# him register map
Vendor: Texas Instruments
Peripheral module from a debugger description file (folder sc4e129bnczad).
Registers are 32-bit, read-write, no defined reset value unless marked. A register's access mark holds for its fields unless they carry their own. Offsets are as the file gives them; lines under a group give offsets from that group; [hi:lo] are bit positions; {n}, {i} and the like mark numbered series; 'fields as' and 'values as' point back to an identical list; <NAME> marks a mode.

## HIM0 — Human Interface Module register offsets
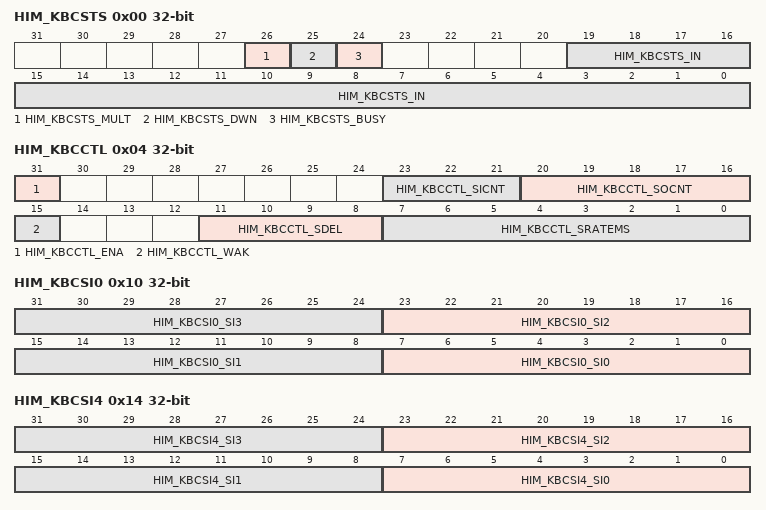
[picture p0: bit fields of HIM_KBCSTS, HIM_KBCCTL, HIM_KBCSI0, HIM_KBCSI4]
0x00 HIM_KBCSTS ro — HIM KBC Status
  [26] HIM_KBCSTS_MULT — Multi-key Detect
  [25] HIM_KBCSTS_DWN — Key Down
  [24] HIM_KBCSTS_BUSY — Scan Busy
  [19:0] HIM_KBCSTS_IN — Scan-Input Byte Change
0x04 HIM_KBCCTL — HIM KBC Control
  [31] HIM_KBCCTL_ENA — Key Scan Enable
  [23:21] HIM_KBCCTL_SICNT — Scan-In Pins
  [20:16] HIM_KBCCTL_SOCNT — Scan-Out Pins
  [15] HIM_KBCCTL_WAK — Wake Test Enable
  [11:8] HIM_KBCCTL_SDEL — Scan-in Delay
  [7:0] HIM_KBCCTL_SRATEMS — Sample Rate (in ms)
0x10 HIM_KBCSI0 ro — HIM KBC Scan-In 0
  [8n+7:8n] HIM_KBCSI0_SI{n} (n=0..3) — SI{n} Read Key States
0x14 HIM_KBCSI4 ro — HIM KBC Scan-In 4
  [8n+7:8n] HIM_KBCSI4_SI{n} (n=0..3) — SI{n} Read Key States
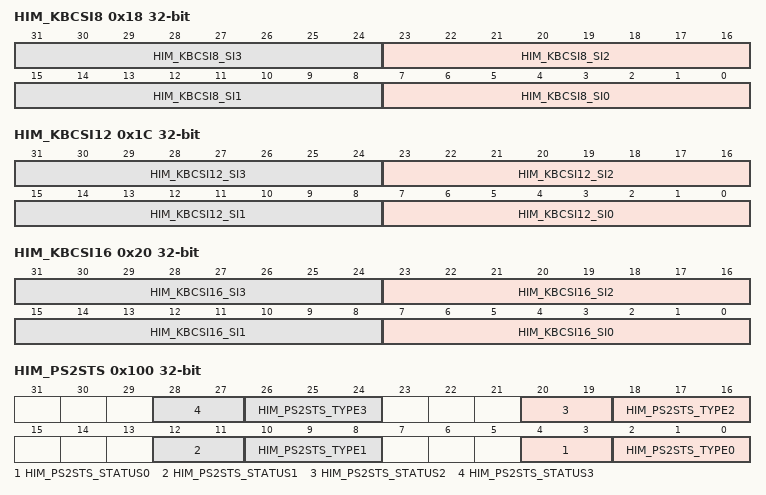
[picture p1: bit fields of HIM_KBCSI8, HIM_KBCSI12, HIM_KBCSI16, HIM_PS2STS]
0x18 HIM_KBCSI8 ro — HIM KBC Scan-In 8
  [8n+7:8n] HIM_KBCSI8_SI{n} (n=0..3) — SI{n} Read Key States
0x1C HIM_KBCSI12 ro — HIM KBC Scan-In 12
  [8n+7:8n] HIM_KBCSI12_SI{n} (n=0..3) — SI{n} Read Key States
0x20 HIM_KBCSI16 ro — HIM KBC Scan-In 16
  [8n+7:8n] HIM_KBCSI16_SI{n} (n=0..3) — SI{n} Read Key States
0x100 HIM_PS2STS ro — HIM PS/2 Status
  [8n+4:8n+3] HIM_PS2STS_STATUS{n} (n=0..3) — PS/2 Bus {n} Line Status
    0=HIM_PS2STS_STATUS{n}_IDLE (Idle); 1=HIM_PS2STS_STATUS{n}_INHIBIT (Inhibited); 2=HIM_PS2STS_STATUS{n}_BUSY (Busy); 3=HIM_PS2STS_STATUS{n}_TRANSIT (Bus is transitioning)
  [8n+2:8n] HIM_PS2STS_TYPE{n} (n=0..3) — Data Type Received
    0=HIM_PS2STS_TYPE{n}_NODATA (No Data Received); 1=HIM_PS2STS_TYPE{n}_ACK (ACK); 2=HIM_PS2STS_TYPE{n}_ERESPS (Error in response to command); 3=HIM_PS2STS_TYPE{n}_CMD (Response to command); 6=HIM_PS2STS_TYPE{n}_ERR (Captured error); 7=HIM_PS2STS_TYPE{n}_DATA (Captured received data)
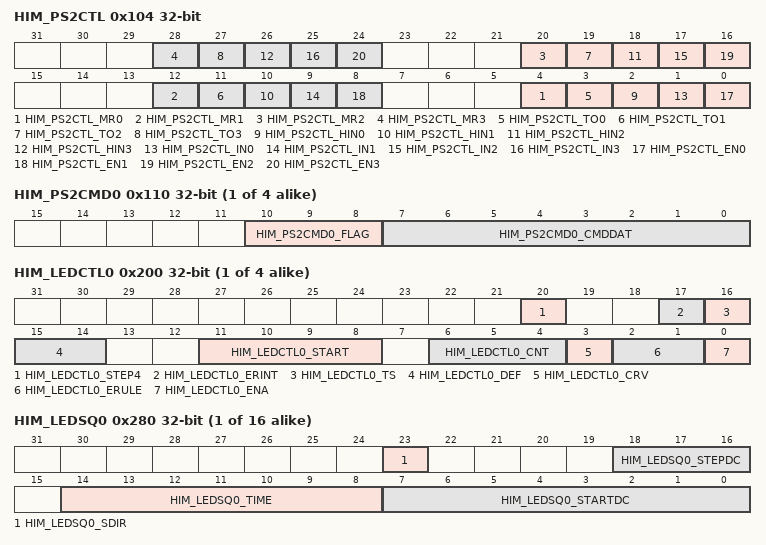
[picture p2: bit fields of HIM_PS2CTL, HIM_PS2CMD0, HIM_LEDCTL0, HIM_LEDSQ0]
0x104 HIM_PS2CTL — HIM PS/2 Control
  [8n+4] HIM_PS2CTL_MR{n} (n=0..3) — More Read Data Indication PS/2 Bus {n}
  [8n+3] HIM_PS2CTL_TO{n} (n=0..3) — Time Out Detection Enable PS/2 Bus {n}
  [8n+2] HIM_PS2CTL_HIN{n} (n=0..3) — Hold Inhibit State Enable PS/2 Bus {n}
  [8n+1] HIM_PS2CTL_IN{n} (n=0..3) — Inhibit Enable PS/2 Bus {n}
  [8n] HIM_PS2CTL_EN{n} (n=0..3) — PS/2 Bus {n} Enable
{0x110+8i} HIM_PS2CMD{i} (i=0..3) — HIM PS/2 {i} Command
  [10:8] HIM_PS2CMD{i}_FLAG — PS/2 Command Flags
    0=HIM_PS2CMD{i}_FLAG_NONE (No ACK Expected); 1=HIM_PS2CMD{i}_FLAG_NOACK (Response Data expected back with no ACK); 2=HIM_PS2CMD{i}_FLAG_NOACK_2 (No ACK with two bytes of Response Data expected back); 3=HIM_PS2CMD{i}_FLAG_NOACK_3 (No ACK with three bytes of Response Data expected back); 4=HIM_PS2CMD{i}_FLAG_ACK (ACK (0xFA) expected proceeded by 0 to 3 bytes of data); 5=HIM_PS2CMD{i}_FLAG_ACK_1 (ACK with one byte of Response Data expected back); 6=HIM_PS2CMD{i}_FLAG_ACK_2 (ACK with two bytes of Response Data expected back); 7=HIM_PS2CMD{i}_FLAG_ACK_3 (ACK with three bytes of Response Data expected back)
  [7:0] HIM_PS2CMD{i}_CMDDAT — Command Data
{0x114+8i} HIM_PS2RDAT{i} (i=0..3) — HIM PS/2 {i} Receive Data
  [7:0] HIM_PS2RDAT{i}_DATA — Last Data Byte
{0x200+4i} HIM_LEDCTL{i} (i=0..3) — LED {i} Control
  [20] HIM_LEDCTL{i}_STEP4 — Step Rule
  [17] HIM_LEDCTL{i}_ERINT — Reverse Mode End Rule (ERULE) Interrupt Control
  [16] HIM_LEDCTL{i}_TS — Tri-stated Off
  [15:14] HIM_LEDCTL{i}_DEF — Default Duty Cycle State
    0=HIM_LEDCTL{i}_DEF_LAST (The LED duty cycle is the (final) value that exists at end of rule with stop); 1=HIM_LEDCTL{i}_DEF_ZERO (The LED duty cycle is 0 (off) at the end of rule with stop); 2=HIM_LEDCTL{i}_DEF_FULL (The LED duty cycle is 0xFF (full on) at the end of rule with stop); 3=HIM_LEDCTL{i}_DEF_HALF (The LED duty cycle is 0x80 (50% on) at the end of rule with stop)
  [11:8] HIM_LEDCTL{i}_START — Start Index
  [6:4] HIM_LEDCTL{i}_CNT — Sequence Count
  [3] HIM_LEDCTL{i}_CRV — Curve Rule
  [2:1] HIM_LEDCTL{i}_ERULE — End Rule
    0=HIM_LEDCTL{i}_ERULE_STOF (Start over from 1st (repeat)); 1=HIM_LEDCTL{i}_ERULE_STOP (Stop when done); 2=HIM_LEDCTL{i}_ERULE_REST (Reverse at end and start (repeat)); 3=HIM_LEDCTL{i}_ERULE_RSTF (Reverse and then stop at first)
  [0] HIM_LEDCTL{i}_ENA — LED Enable
{0x280+4i} HIM_LEDSQ{i} (i=0..15) — HIM LED {i} Sequence
  [23] HIM_LEDSQ{i}_SDIR — Step Direction
  [18:16] HIM_LEDSQ{i}_STEPDC — Duty-cycle Step
    0=HIM_LEDSQ{i}_STEPDC_NONE (No stepping. STARTDC is held); 1=HIM_LEDSQ{i}_STEPDC_1P8PWM (Duty cycle is changed by 1/8 per PWM period); 2=HIM_LEDSQ{i}_STEPDC_1P4PWM (Duty cycle is changed by 1/4 per PWM period); 3=HIM_LEDSQ{i}_STEPDC_1P2PWM (Duty cycle is changed by 1/2 per PWM period); 4=HIM_LEDSQ{i}_STEPDC_1P1PWM (Duty cycle is changed by 1 every PWM period); 5=HIM_LEDSQ{i}_STEPDC_2P1PWM (Duty cycle is changed by 2 every PWM period); 6=HIM_LEDSQ{i}_STEPDC_4P1PWM (Duty cycle is changed by 4 every PWM period); 7=HIM_LEDSQ{i}_STEPDC_8P1PWM (Dutycycle is changed by 8 every PWM period)
  [14:8] HIM_LEDSQ{i}_TIME — Sequence Time
  [7:0] HIM_LEDSQ{i}_STARTDC — Starting Duty Cycle Value
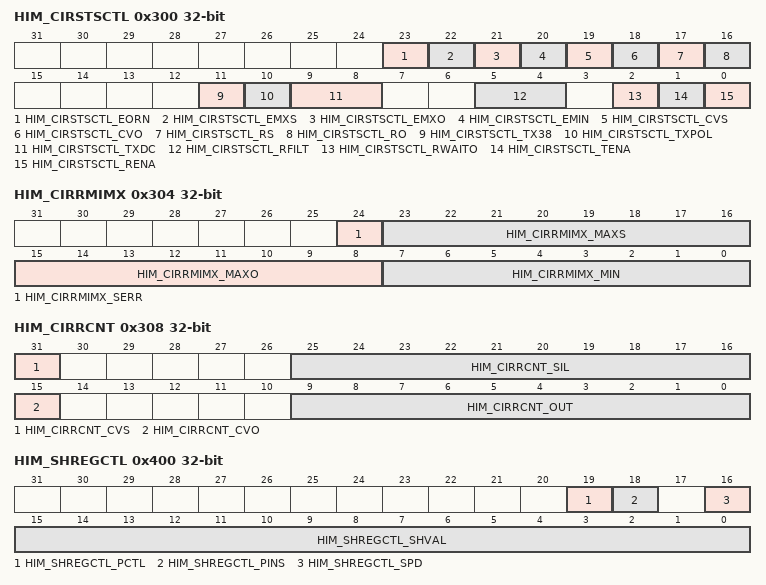
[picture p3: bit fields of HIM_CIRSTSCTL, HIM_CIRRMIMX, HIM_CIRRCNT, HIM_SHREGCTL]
0x300 HIM_CIRSTSCTL — HIM CIR Status and Control
  [23] HIM_CIRSTSCTL_EORN — Overrun Error Status
  [22] HIM_CIRSTSCTL_EMXS — Maximum Silence Error Status
  [21] HIM_CIRSTSCTL_EMXO — Maximum Output Period Error
  [20] HIM_CIRSTSCTL_EMIN — Minimum Output or Silence Period Error
  [19] HIM_CIRSTSCTL_CVS — Silence Count Valid Status
  [18] HIM_CIRSTSCTL_CVO — Output Count Valid
  [17] HIM_CIRSTSCTL_RS — Receive Silence Status
  [16] HIM_CIRSTSCTL_RO — Receiving Output Status
  [11] HIM_CIRSTSCTL_TX38 — Modulate Output
  [10] HIM_CIRSTSCTL_TXPOL — Swap Polarity
  [9:8] HIM_CIRSTSCTL_TXDC — Modulated Output Duty Cycle
    0=HIM_CIRSTSCTL_TXDC_25PCT (25%); 1=HIM_CIRSTSCTL_TXDC_33PCT (33%); 2=HIM_CIRSTSCTL_TXDC_50PCT (50%)
  [5:4] HIM_CIRSTSCTL_RFILT — Input Filter Rule
    0=1 period filtering; 1=2 period filtering; 2=4 period filtering; 3=8 period filtering
  [2] HIM_CIRSTSCTL_RWAITO — Receiver Wait Output Period Enable
  [1] HIM_CIRSTSCTL_TENA — Transmit Enable
  [0] HIM_CIRSTSCTL_RENA — Receive Enable
0x304 HIM_CIRRMIMX ro — HIM CIR Min and Max Receive Count
  [24] HIM_CIRRMIMX_SERR — Max Silence Configuration
  [23:16] HIM_CIRRMIMX_MAXS — Maximum Silence Period
  [15:8] HIM_CIRRMIMX_MAXO — Maximum Output Period
  [7:0] HIM_CIRRMIMX_MIN — Minimum Output or Silence Period
0x308 HIM_CIRRCNT ro — HIM CIR Receive Count
  [31] HIM_CIRRCNT_CVS — Silent Count is Valid
  [25:16] HIM_CIRRCNT_SIL — Silence Count
  [15] HIM_CIRRCNT_CVO — OUT Valid
  [9:0] HIM_CIRRCNT_OUT — Output Count
0x310 HIM_CIRTCNT — HIM CIR Transmit Count
  [31] HIM_CIRTCNT_SP — SIL Pending
  [31] HIM_CIRTCNT_SIGN — Silence Ignore
  [25:16] HIM_CIRTCNT_SIL — Silence Count
  [15] HIM_CIRTCNT_OP — OUT Pending
  [15] HIM_CIRTCNT_OIGN — Ignore OUT
  [9:0] HIM_CIRTCNT_OUT — Output Count
0x400 HIM_SHREGCTL — HIM Shift Register Control
  [19] HIM_SHREGCTL_PCTL — Pin Control
  [18] HIM_SHREGCTL_PINS — Pin Selection
  [16] HIM_SHREGCTL_SPD — Speed of Clock
  [15:0] HIM_SHREGCTL_SHVAL — Shift Register
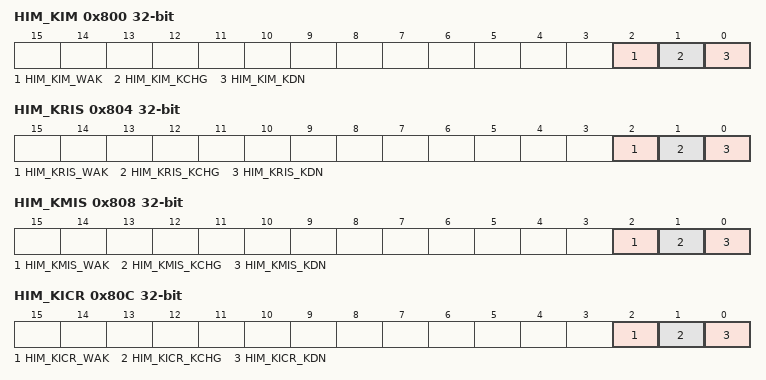
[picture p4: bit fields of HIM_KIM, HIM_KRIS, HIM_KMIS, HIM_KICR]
0x800 HIM_KIM — HIM KBC Interrupt Mask
  [2] HIM_KIM_WAK — Wake from Ganged Detect Interrupt Mask
  [1] HIM_KIM_KCHG — Keyboard Change Detect Interrupt Mask
  [0] HIM_KIM_KDN — Keyboard Scan Done Interrupt Mask
0x804 HIM_KRIS ro — HIM KBC Raw Interrupt Status
  [2] HIM_KRIS_WAK — Wake from Ganged Detect Raw Interrupt Status
  [1] HIM_KRIS_KCHG — Keyboard Change Detect Raw Interrupt Status
  [0] HIM_KRIS_KDN — Keyboard Scan Done Raw Interrupt Status
0x808 HIM_KMIS ro — HIM KBC Masked Interrupt Status
  [2] HIM_KMIS_WAK — Wake from Ganged detect Masked Interrupt Status
  [1] HIM_KMIS_KCHG — Keyboard Change Detect Masked Interrupt Status
  [0] HIM_KMIS_KDN — Keyboard Scan Done Masked Interrupt Status
0x80C HIM_KICR — HIM KBC Interrupt Clear
  [2] HIM_KICR_WAK — Wake from Ganged Detect Interrupt Clear
  [1] HIM_KICR_KCHG — Keyboard Change Interrupt Clear
  [0] HIM_KICR_KDN — Keyboard Scan Done Interrupt Clear
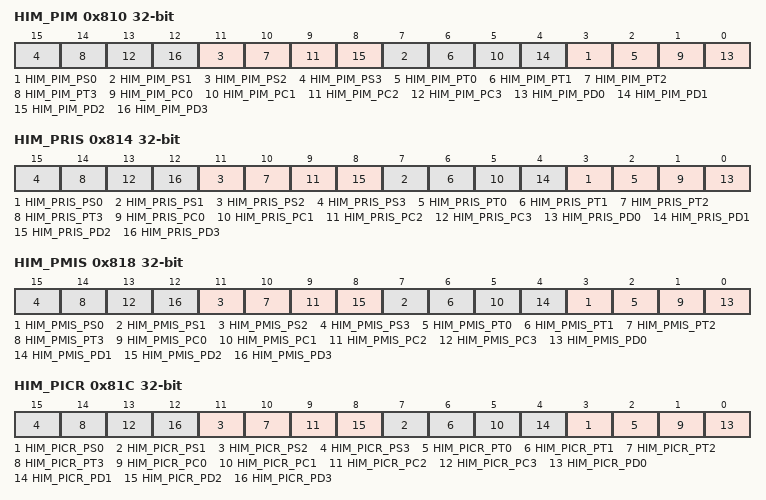
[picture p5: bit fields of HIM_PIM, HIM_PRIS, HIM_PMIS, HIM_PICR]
0x810 HIM_PIM — HIM PS/2 Interrupt Mask
  [4n+3] HIM_PIM_PS{n} (n=0..3) — PS/2 Bus {n} Command Byte Sent Interrupt Mask
  [4n+2] HIM_PIM_PT{n} (n=0..3) — PS/2 Bus {n} Timeout Interrupt Mask
  [4n+1] HIM_PIM_PC{n} (n=0..3) — PS/2 Bus {n} Capture Data Arrived Interrupt Mask
  [4n] HIM_PIM_PD{n} (n=0..3) — PS/2 Bus {n} Command Data Arrived Interrupt Mask
0x814 HIM_PRIS ro — HIM PS/2 Raw Interrupt Status
  [4n+3] HIM_PRIS_PS{n} (n=0..3) — PS/2 Bus {n} Command Byte Sent Raw Interrupt Status
  [4n+2] HIM_PRIS_PT{n} (n=0..3) — PS/2 Bus {n} Timeout Raw Interrupt Status
  [4n+1] HIM_PRIS_PC{n} (n=0..3) — PS/2 Bus {n} Capture Data Arrived Raw Interrupt Status
  [4n] HIM_PRIS_PD{n} (n=0..3) — PS/2 Bus {n} Command Data Arrived Raw Interrupt Status
0x818 HIM_PMIS ro — HIM PS/2 Masked Interrupt Status
  [4n+3] HIM_PMIS_PS{n} (n=0..3) — PS/2 Bus {n} Command Byte Sent Masked Interrupt Status
  [4n+2] HIM_PMIS_PT{n} (n=0..3) — PS/2 Bus {n} Timeout Masked Interrupt Status
  [4n+1] HIM_PMIS_PC{n} (n=0..3) — PS/2 Bus {n} Capture Data Arrived Masked Interrupt Status
  [4n] HIM_PMIS_PD{n} (n=0..3) — PS/2 Bus {n} Command Data Arrived Masked Interrupt Status
0x81C HIM_PICR — HIM PS/2 Interrupt Clear
  [4n+3] HIM_PICR_PS{n} (n=0..3) — PS/2 Bus {n} Command Byte Sent Interrupt Clear
  [4n+2] HIM_PICR_PT{n} (n=0..3) — PS/2 Bus {n} Timeout Interrupt Clear
  [4n+1] HIM_PICR_PC{n} (n=0..3) — PS/2 Bus {n} Capture Data Arrived Interrupt Clear
  [4n] HIM_PICR_PD{n} (n=0..3) — PS/2 Bus {n} Command Data Arrived Interrupt Clear
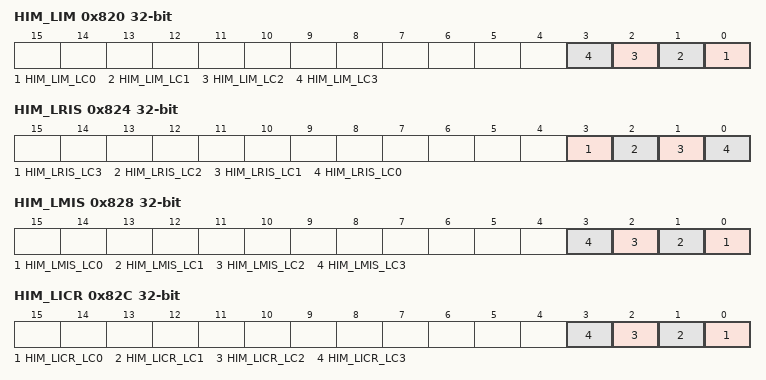
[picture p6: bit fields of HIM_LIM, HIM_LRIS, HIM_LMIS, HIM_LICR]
0x820 HIM_LIM — HIM LED Interrupt Mask
  [n] HIM_LIM_LC{n} (n=0..3) — LED {n} Sequencer Complete Interrupt Mask
0x824 HIM_LRIS ro — HIM LED Raw Interrupt Status
  [3] HIM_LRIS_LC3 — LED Sequencer 3 Complete Raw Interrupt Status
  [2] HIM_LRIS_LC2 — LED 2 Sequencer Complete Raw Interrupt Status
  [1] HIM_LRIS_LC1 — LED 1 Sequencer Complete Raw Interrupt Status
  [0] HIM_LRIS_LC0 — LED 0 Sequencer Complete Raw Interrupt Status
0x828 HIM_LMIS ro — HIM LED Masked Interrupt Status
  [n] HIM_LMIS_LC{n} (n=0..3) — LED {n} Sequencer Complete Masked Interrupt Status
0x82C HIM_LICR — HIM LED Interrupt Clear
  [n] HIM_LICR_LC{n} (n=0..3) — LED {n} Sequencer Complete Interrupt Clear
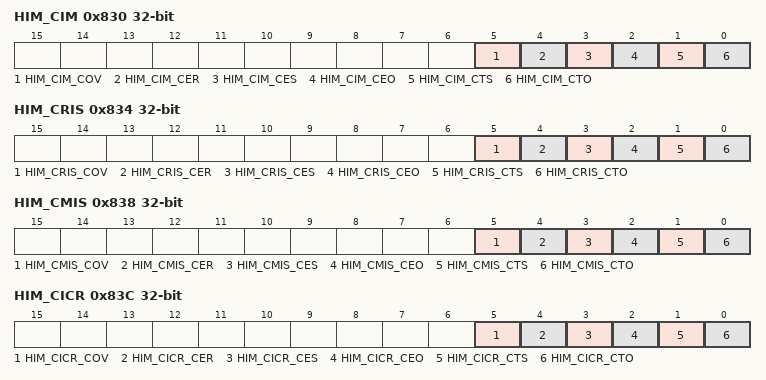
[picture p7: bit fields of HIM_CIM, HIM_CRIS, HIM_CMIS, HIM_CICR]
0x830 HIM_CIM — HIM CIR Interrupt Mask
  [5] HIM_CIM_COV — CIR Overrun Error Interrupt Mask
  [4] HIM_CIM_CER — CIR Receive Error Interrupt Mask
  [3] HIM_CIM_CES — CIR Receive Silence Period End Interrupt Mask
  [2] HIM_CIM_CEO — CIR Received Output Period End Interrupt Mask
  [1] HIM_CIM_CTS — CIR Transmitter Silence Counter Done Interrupt Mask
  [0] HIM_CIM_CTO — CIR Transmitter Modulated Output Counter Done Interrupt Mask
0x834 HIM_CRIS ro — HIM CIR Raw Interrupt Status
  [5] HIM_CRIS_COV — CIR Overrun Error Raw Interrupt Status
  [4] HIM_CRIS_CER — CIR Receive Error Raw Interrupt Status
  [3] HIM_CRIS_CES — CIR Received Silence Period End Raw Interrupt Status
  [2] HIM_CRIS_CEO — CIR Received Output Period End Raw Interrupt Status
  [1] HIM_CRIS_CTS — CIR Transmitter Silence Counter Done Raw Interrupt Status
  [0] HIM_CRIS_CTO — CIR Transmitter Modulated Output Counter Done Raw Interrupt Status
0x838 HIM_CMIS ro — HIM CIR Masked Interrupt Status
  [5] HIM_CMIS_COV — CIR Overrun Error Raw Interrupt Status
  [4] HIM_CMIS_CER — CIR Receive Error Masked Interrupt Status
  [3] HIM_CMIS_CES — CIR Receive Silence Period End Masked Interrupt Status
  [2] HIM_CMIS_CEO — CIR Received Output Period End Masked Interrupt Status
  [1] HIM_CMIS_CTS — CIR Transmitter Silence Counter Done Masked Interrupt Status
  [0] HIM_CMIS_CTO — CIR Transmitter Modulated Output Counter Done Masked Interrupt Status
0x83C HIM_CICR — HIM CIR Interrupt Clear
  [5] HIM_CICR_COV — CIR Overrun Error Raw Interrupt Status
  [4] HIM_CICR_CER — CIR Receiver Detected Error Interrupt Clear
  [3] HIM_CICR_CES — CIR Received Silence Period Ended Interrupt Clear
  [2] HIM_CICR_CEO — CIR Received Output Period Ended Interrupt Clear
  [1] HIM_CICR_CTS — CIR Transmitter Silence Counter Interrupt Clear
  [0] HIM_CICR_CTO — CIR Transmitter Modulated Output Done Interrupt Clear
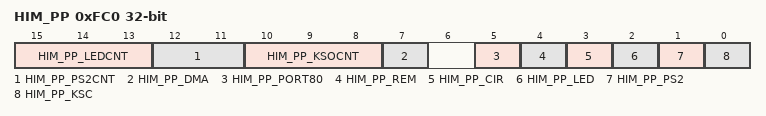
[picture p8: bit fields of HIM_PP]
0xFC0 HIM_PP ro — HIM Peripheral Properties
  [15:13] HIM_PP_LEDCNT — Number of Supported LED
  [12:11] HIM_PP_PS2CNT — Number of PS/2 Supported Buses
  [10:8] HIM_PP_KSOCNT — Scan-Out GPIOs Allowed
    0=HIM_PP_KSOCNT_8SOGPIO (8 scan-out GPIOs); 1=HIM_PP_KSOCNT_16SOGPIO (16 scan-out GPIOs); 2=HIM_PP_KSOCNT_18SOGPIO (18 scan-out GPIOs); 3=HIM_PP_KSOCNT_20SOGPIO (20 scan-out GPIOs)
  [7] HIM_PP_DMA — uDMA Support
  [5] HIM_PP_PORT80 — Port 80 (Shift Register) Support
  [4] HIM_PP_REM — Remote HIM Support
  [3] HIM_PP_CIR — Consumer IR Support
  [2] HIM_PP_LED — LED Support
  [1] HIM_PP_PS2 — PS/2 Support
  [0] HIM_PP_KSC — Keyscan Support
